# MDR1901VC1 register map
Vendor: Milandr; Series: ARMCM3; File version: 2.0
ARM 32-bit Cortex-M3 Microcontroller based device with DSP Core, CPU clock up to 100MHz, etc.
CPU: CM3 r2p1, little endian, no MPU, no FPU, 3 interrupt priority bits
Registers are 32-bit, read-write, reset 0x0 unless marked. A register's access mark holds for its fields unless they carry their own. Offsets are from the block's base; lines under a group give offsets from that group; [hi:lo] are bit positions; {n}, {i} and the like mark numbered series; 'fields as' and 'values as' point back to an identical list; <NAME> marks a mode.

## Memory map
0x40000000 MDR_SSP3 size 0x28
0x40008000 MDR_SSP4 size 0x28
0x40018000 MDR_EEPROM size 0x14 — EEPROM Control
0x40020000 MDR_RST_CLOCK size 0x3C — CLock Control
0x40040000 MDR_SSP1 size 0x28 — Synchronous Serial Port
0x40088000 MDR_ADC size 0x30 — Successive Approximation ADC
0x400A0000 MDR_SSP2 size 0x28
0x400A8000 MDR_PORTA size 0x20 — GPIO Port Control
0x400B0000 MDR_PORTB size 0x20
0x400B8000 MDR_PORTC size 0x20
0x400C0000 MDR_PORTD size 0x20
0x400C8000 MDR_PORTE size 0x20
0x400D8000 MDR_BKP size 0x54 — Backup and RTC Control
0x400E8000 MDR_PORTF size 0x20

## MDR_EEPROM — EEPROM Control
Base 0x40018000
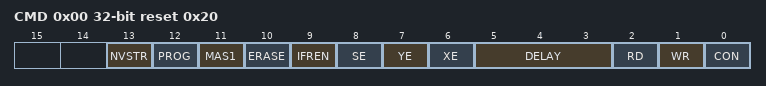
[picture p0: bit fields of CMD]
0x00 CMD reset 0x20 (reset mask 0x3FF) — EEPROM Control register
  [13] NVSTR — Memory access mode
    0=Read mode; 1=Write (Programming or erase mode)
  [12] PROG — Programm EEPROM_DI to ADDR[16:0]
    0=Inactive (No programm operation); 1=Active (Programm operation)
  [11] MAS1 — Erase whole block with ERASE
    0=Off (Disable); 1=On (Enable)
  [10] ERASE — Erase string at ADDR[16:0]
    0=Inactive (No erase operation); 1=Active (Erase operation)
  [9] IFREN — Select main or info memory
    0=Main memory; 1=Info memory
  [8] SE — RD Amplifier enable
    0=Off (Disable); 1=On (Enable)
  [7] YE — Enable ADDR[8..2]
    0=Off (Disable); 1=On (Enable)
  [6] XE — Enable ADDR[16..9]
    0=Off (Disable); 1=On (Enable)
  [5:3] DELAY — Memory access CPU delay tacts
    0=le25MHz (CPU freq is up to 25MHz); 1=le50MHz (CPU freq is up to 50MHz); 2=le75MHz (CPU freq is up to 75MHz); 3=le100MHz (CPU freq is up to 100MHz); 4=le125MHz (CPU freq is up to 125MHz); 5=le150MHz (CPU freq is up to 150MHz); 6=le175MHz (CPU freq is up to 175MHz); 7=le200MHz (CPU freq is up to 200MHz)
  [2] RD — Read operation, (test bit)
    0=Inactive (No read operation); 1=Active (Read operation)
  [1] WR — Write operation (test bit)
    0=Inactive (No write operation); 1=Active (Write operation)
  [0] CON — Enable memory access through EEPROM controller
    0=Normal access to memory; 1=Controller Access (Access to memory though registers)
0x04 ADDR — Address register
0x08 DI — Write data register
0x0C DO — Read data register
0x10 KEY — Unlock block register

## MDR_SSP1 — Synchronous Serial Port
Base 0x40040000
Same registers: MDR_SSP3 0x40000000, MDR_SSP4 0x40008000, MDR_SSP2 0x400A0000
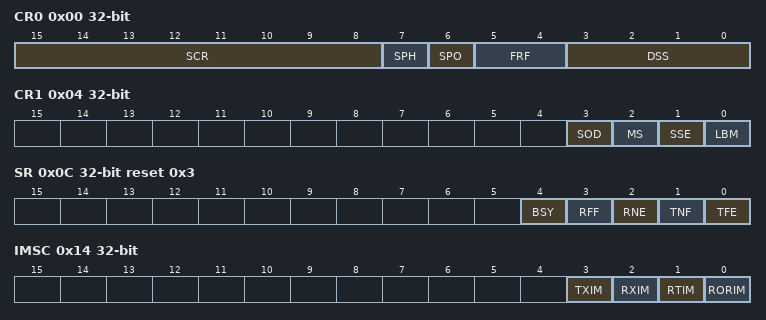
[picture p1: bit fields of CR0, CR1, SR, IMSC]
0x00 CR0 — Control Register 0
  [15:8] SCR — Signal CLock Rate
  [7] SPH — SPI Capture Clock Phase
    0=Leading (Capture data on leading edge); 1=Trailing (Capture data on trailing edge)
  [6] SPO — SPI Clock Polarity
    0=Idle_Low (Idle state is Low); 1=Idle_High (Idle state is High)
  [5:4] FRF — Frame Format
    0=SPI (Motorola SPI protocol); 1=SSI (Texas Instruments SSI protocol); 2=Microwire (National Semiconductor Microwire protocol)
  [3:0] DSS — Data Size Select
    {v}=bits_{v+1} (Word of {v+1} bits) (v=3..15)
0x04 CR1 — Control Register 1
  [3] SOD — Slave mode Output Disable
    0=SlaveTxEna (Slave mode transmit enable); 1=SlaveTxDis (Slave mode transmit disable)
  [2] MS — Master or Slave mode
    0=Master Mode; 1=Slave Mode
  [1] SSE — Synchronous Serial Enable
    0=Off (SSP Disable); 1=On (SSP Enable)
  [0] LBM — Loop Back Mode
    0=Normal operation; 1=LoopBack (TX send to RX test mode)
0x08 DR — FIFO_Rx and FIFO_Tx access
  [15:0] Data — Data value
0x0C SR ro reset 0x3 — Status Register
  [4] BSY — Transfer in progress
    0=Idle (FIFO_RX is Not Full); 1=Busy (Transfering)
  [3] RFF — FIFO_RX is Full
    0=RX_NotFull (FIFO_RX is Not Full); 1=RX_Full (FIFO_RX is Full)
  [2] RNE — FIFO_RX is Not Empty
    0=RX_NotEmpty (FIFO_RX is Empty); 1=RX_Empty (FIFO_RX is Not Empty)
  [1] TNF — FIFO_TX is Not Full
    0=TX_Full (FIFO_TX is Full); 1=TX_NotFull (FIFO_TX is Not Full)
  [0] TFE — FIFO_TX is Empty
    0=TX_NotEmpty (FIFO_TX is Not Empty); 1=TX_Empty (FIFO_TX is Empty)
0x10 CPSR — Clock Prescaller Register
  [7:0] CPSDVSR — Clock Prescaller
0x14 IMSC — IRQ Mask Set-Clear
  [3] TXIM — Enable IQR on FIFO_TX le 4 words
    0=NoEvent (Flag Inactive); 1=TX_HalfEmpty (Flag Active)
  [2] RXIM — Enable IQR on FIFO_RX ge 4 words
    0=NoEvent (Flag Inactive); 1=RX_HalfFull (Flag Active)
  [1] RTIM — Enable IQR on RX timeout for 32bits
    0=NoEvent (Flag Inactive); 1=RX_Timeout (Flag Active)
  [0] RORIM — Enable IRQ on FIFO_RX overrun
    0=NoEvent (Flag Inactive); 1=RX_Overrun (Flag Active)
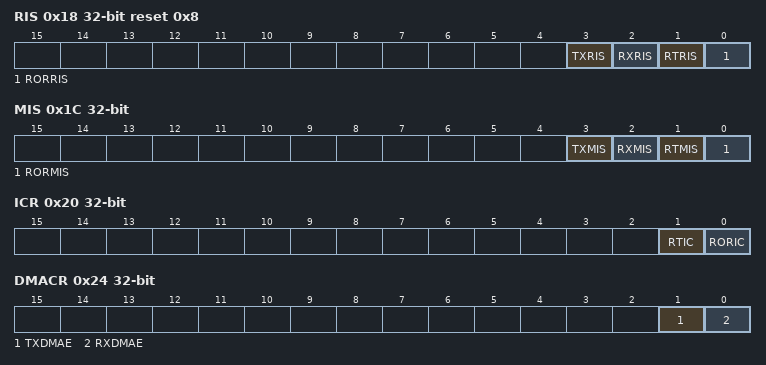
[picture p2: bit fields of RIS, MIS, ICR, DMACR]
0x18 RIS ro reset 0x8 — Raw Interupt Status
  [3] TXRIS — FIFO_TX le words
    0=NoEvent (Flag Inactive); 1=TX_HalfEmpty (Flag Active)
  [2] RXRIS — FIFO_RX gt words
    0=NoEvent (Flag Inactive); 1=RX_HalfFull (Flag Active)
  [1] RTRIS — RX timeout for 32bits
    0=NoEvent (Flag Inactive); 1=RX_Timeout (Flag Active)
  [0] RORRIS — FIFO_RX is overrun
    0=NoEvent (Flag Inactive); 1=RX_Overrun (Flag Active)
0x1C MIS ro — Masked Interupt Status
  [3] TXMIS — FIFO_TX le 4 words
    0=NoEvent (Flag Inactive); 1=TX_HalfEmpty (Flag Active)
  [2] RXMIS — FIFO_RX ge 4 words
    0=NoEvent (Flag Inactive); 1=RX_HalfFull (Flag Active)
  [1] RTMIS — RX timeout for 32bits
    0=NoEvent (Flag Inactive); 1=RX_Timeout (Flag Active)
  [0] RORMIS — FIFO_RX is overrun
    0=NoEvent (Flag Inactive); 1=RX_Overrun (Flag Active)
0x20 ICR wo — Interupt Clear Register
  [1] RTIC — Clear RX timeout flag
    0=Inactive (No action); 1=Clear Flag
  [0] RORIC — Clear FIFO_RX overrun flag
    0=Inactive (No action); 1=Clear Flag
0x24 DMACR — DMA Control Register
  [1] TXDMAE — Enable DMA by FIFO_TX not Full
    0=Disable DMA; 1=Enable DMA
  [0] RXDMAE — Enable DMA by FIFO_RX has data
    0=Disable DMA; 1=Enable DMA
